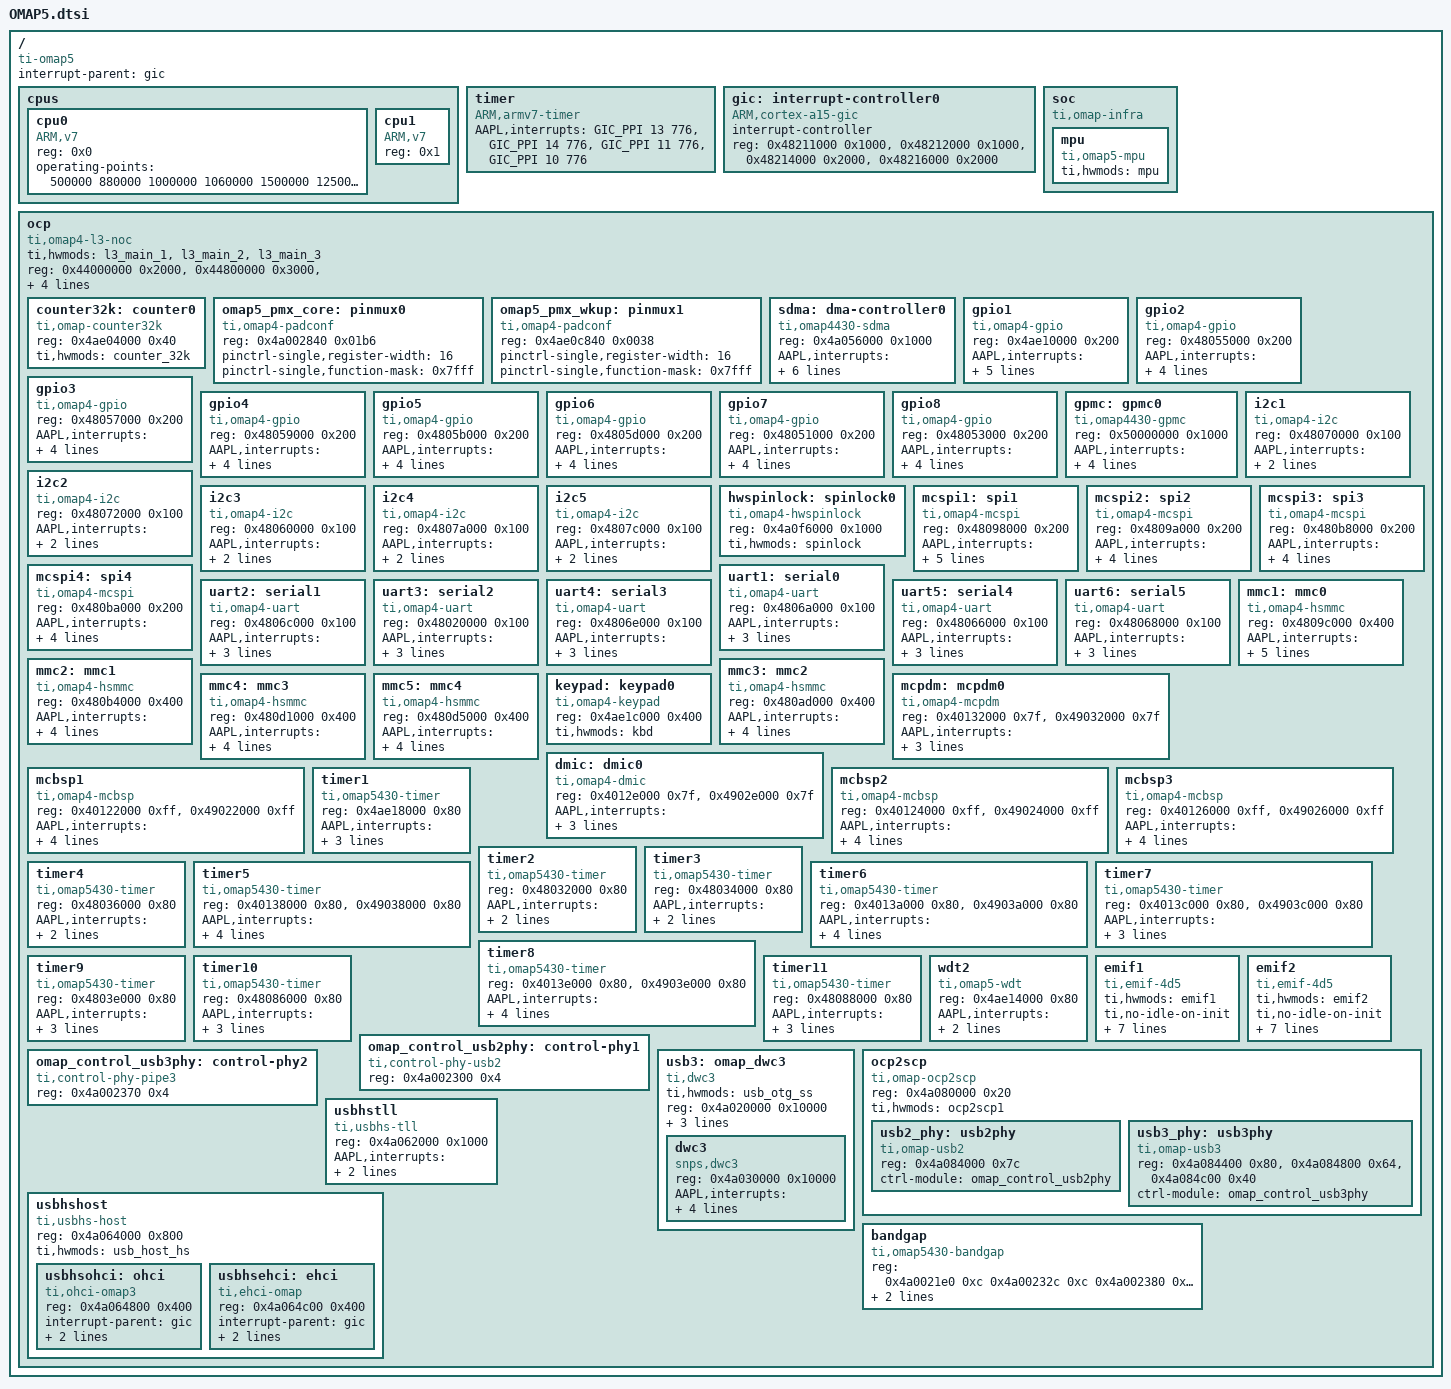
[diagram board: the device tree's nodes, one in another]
/*
 * Copyright (C) 2012 Texas Instruments Incorporated - http://www.ti.com/
 *
 * This program is free software; you can redistribute it and/or modify
 * it under the terms of the GNU General Public License version 2 as
 * published by the Free Software Foundation.
 * Based on "omap4.dtsi"
 */

#include <dt-bindings/interrupt-controller/arm-gic.h>

/ {
	compatible = "ti-omap5", "AppleARM";
	#address-cells = <1>;
	#size-cells = <1>;
	interrupt-parent = <&gic>;
	
	cpus {
		#address-cells = <1>;
		#size-cells = <0>;

		cpu0 {
			device_type = "cpu";
			compatible = "ARM,v7", "ARM,cortex-a15";
			reg = <0x0>;

			operating-points = <
				/* kHz    uV */
				500000  880000
				1000000 1060000
				1500000 1250000
			>;
		};
		cpu1 {
			device_type = "cpu";
			compatible = "ARM,v7", "ARM,cortex-a15";
			reg = <0x1>;
		};
	};

	timer {
		compatible = "ARM,armv7-timer";
		/* PPI secure/nonsecure IRQ */
		AAPL,interrupts = <GIC_PPI 13 776>,
			     <GIC_PPI 14 776>,
			     <GIC_PPI 11 776>,
			     <GIC_PPI 10 776>;
	};

	gic: interrupt-controller0 {
		compatible = "ARM,cortex-a15-gic";
		interrupt-controller;
		#interrupt-cells = <3>;
		reg = <0x48211000 0x1000>,
		      <0x48212000 0x1000>,
		      <0x48214000 0x2000>,
		      <0x48216000 0x2000>;
	};

	/*
	 * The soc node represents the soc top level view. It is uses for IPs
	 * that are not memory mapped in the MPU view or for the MPU itself.
	 */
	soc {
		compatible = "ti,omap-infra";
		mpu {
			compatible = "ti,omap5-mpu";
			ti,hwmods = "mpu";
		};
	};

	/*
	 * XXX: Use a flat representation of the OMAP3 interconnect.
	 * The real OMAP interconnect network is quite complex.
	 * Since that will not bring real advantage to represent that in DT for
	 * the moment, just use a fake OCP bus entry to represent the whole bus
	 * hierarchy.
	 */
	ocp {
		compatible = "ti,omap4-l3-noc", "simple-bus";
		#address-cells = <1>;
		#size-cells = <1>;
		ranges;
		ti,hwmods = "l3_main_1", "l3_main_2", "l3_main_3";
		reg = <0x44000000 0x2000>,
		      <0x44800000 0x3000>,
		      <0x45000000 0x4000>;
		AAPL,interrupts = <GIC_SPI 9 IRQ_TYPE_LEVEL_HIGH>,
			     <GIC_SPI 10 IRQ_TYPE_LEVEL_HIGH>;

		counter32k: counter0 {
			compatible = "ti,omap-counter32k";
			reg = <0x4ae04000 0x40>;
			ti,hwmods = "counter_32k";
		};

		omap5_pmx_core: pinmux0 {
			compatible = "ti,omap4-padconf", "pinctrl-single";
			reg = <0x4a002840 0x01b6>;
			#address-cells = <1>;
			#size-cells = <0>;
			pinctrl-single,register-width = <16>;
			pinctrl-single,function-mask = <0x7fff>;
		};
		omap5_pmx_wkup: pinmux1 {
			compatible = "ti,omap4-padconf", "pinctrl-single";
			reg = <0x4ae0c840 0x0038>;
			#address-cells = <1>;
			#size-cells = <0>;
			pinctrl-single,register-width = <16>;
			pinctrl-single,function-mask = <0x7fff>;
		};

		sdma: dma-controller0 {
			compatible = "ti,omap4430-sdma";
			reg = <0x4a056000 0x1000>;
			AAPL,interrupts = <GIC_SPI 12 IRQ_TYPE_LEVEL_HIGH>,
				     <GIC_SPI 13 IRQ_TYPE_LEVEL_HIGH>,
				     <GIC_SPI 14 IRQ_TYPE_LEVEL_HIGH>,
				     <GIC_SPI 15 IRQ_TYPE_LEVEL_HIGH>;
			#dma-cells = <1>;
			#dma-channels = <32>;
			#dma-requests = <127>;
		};
		
		gpio1: gpio1 {
			compatible = "ti,omap4-gpio";
			reg = <0x4ae10000 0x200>;
			AAPL,interrupts = <GIC_SPI 29 IRQ_TYPE_LEVEL_HIGH>;
			ti,hwmods = "gpio1";
			ti,gpio-always-on;
			gpio-controller;
			#gpio-cells = <2>;
			interrupt-controller;
			#interrupt-cells = <2>;
		};

		gpio2: gpio2 {
			compatible = "ti,omap4-gpio";
			reg = <0x48055000 0x200>;
			AAPL,interrupts = <GIC_SPI 30 IRQ_TYPE_LEVEL_HIGH>;
			ti,hwmods = "gpio2";
			gpio-controller;
			#gpio-cells = <2>;
			interrupt-controller;
			#interrupt-cells = <2>;
		};

		gpio3: gpio3 {
			compatible = "ti,omap4-gpio";
			reg = <0x48057000 0x200>;
			AAPL,interrupts = <GIC_SPI 31 IRQ_TYPE_LEVEL_HIGH>;
			ti,hwmods = "gpio3";
			gpio-controller;
			#gpio-cells = <2>;
			interrupt-controller;
			#interrupt-cells = <2>;
		};

		gpio4: gpio4 {
			compatible = "ti,omap4-gpio";
			reg = <0x48059000 0x200>;
			AAPL,interrupts = <GIC_SPI 32 IRQ_TYPE_LEVEL_HIGH>;
			ti,hwmods = "gpio4";
			gpio-controller;
			#gpio-cells = <2>;
			interrupt-controller;
			#interrupt-cells = <2>;
		};

		gpio5: gpio5 {
			compatible = "ti,omap4-gpio";
			reg = <0x4805b000 0x200>;
			AAPL,interrupts = <GIC_SPI 33 IRQ_TYPE_LEVEL_HIGH>;
			ti,hwmods = "gpio5";
			gpio-controller;
			#gpio-cells = <2>;
			interrupt-controller;
			#interrupt-cells = <2>;
		};

		gpio6: gpio6 {
			compatible = "ti,omap4-gpio";
			reg = <0x4805d000 0x200>;
			AAPL,interrupts = <GIC_SPI 34 IRQ_TYPE_LEVEL_HIGH>;
			ti,hwmods = "gpio6";
			gpio-controller;
			#gpio-cells = <2>;
			interrupt-controller;
			#interrupt-cells = <2>;
		};

		gpio7: gpio7 {
			compatible = "ti,omap4-gpio";
			reg = <0x48051000 0x200>;
			AAPL,interrupts = <GIC_SPI 35 IRQ_TYPE_LEVEL_HIGH>;
			ti,hwmods = "gpio7";
			gpio-controller;
			#gpio-cells = <2>;
			interrupt-controller;
			#interrupt-cells = <2>;
		};

		gpio8: gpio8 {
			compatible = "ti,omap4-gpio";
			reg = <0x48053000 0x200>;
			AAPL,interrupts = <GIC_SPI 121 IRQ_TYPE_LEVEL_HIGH>;
			ti,hwmods = "gpio8";
			gpio-controller;
			#gpio-cells = <2>;
			interrupt-controller;
			#interrupt-cells = <2>;
		};

		gpmc: gpmc0 {
			compatible = "ti,omap4430-gpmc";
			reg = <0x50000000 0x1000>;
			#address-cells = <2>;
			#size-cells = <1>;
			AAPL,interrupts = <GIC_SPI 20 IRQ_TYPE_LEVEL_HIGH>;
			gpmc,num-cs = <8>;
			gpmc,num-waitpins = <4>;
			ti,hwmods = "gpmc";
		};

		i2c1: i2c1 {
			compatible = "ti,omap4-i2c";
			reg = <0x48070000 0x100>;
			AAPL,interrupts = <GIC_SPI 56 IRQ_TYPE_LEVEL_HIGH>;
			#address-cells = <1>;
			#size-cells = <0>;
			ti,hwmods = "i2c1";
		};

		i2c2: i2c2 {
			compatible = "ti,omap4-i2c";
			reg = <0x48072000 0x100>;
			AAPL,interrupts = <GIC_SPI 57 IRQ_TYPE_LEVEL_HIGH>;
			#address-cells = <1>;
			#size-cells = <0>;
			ti,hwmods = "i2c2";
		};

		i2c3: i2c3 {
			compatible = "ti,omap4-i2c";
			reg = <0x48060000 0x100>;
			AAPL,interrupts = <GIC_SPI 61 IRQ_TYPE_LEVEL_HIGH>;
			#address-cells = <1>;
			#size-cells = <0>;
			ti,hwmods = "i2c3";
		};

		i2c4: i2c4 {
			compatible = "ti,omap4-i2c";
			reg = <0x4807a000 0x100>;
			AAPL,interrupts = <GIC_SPI 62 IRQ_TYPE_LEVEL_HIGH>;
			#address-cells = <1>;
			#size-cells = <0>;
			ti,hwmods = "i2c4";
		};

		i2c5: i2c5 {
			compatible = "ti,omap4-i2c";
			reg = <0x4807c000 0x100>;
			AAPL,interrupts = <GIC_SPI 60 IRQ_TYPE_LEVEL_HIGH>;
			#address-cells = <1>;
			#size-cells = <0>;
			ti,hwmods = "i2c5";
		};

		hwspinlock: spinlock0 {
			compatible = "ti,omap4-hwspinlock";
			reg = <0x4a0f6000 0x1000>;
			ti,hwmods = "spinlock";
		};

		mcspi1: spi1 {
			compatible = "ti,omap4-mcspi";
			reg = <0x48098000 0x200>;
			AAPL,interrupts = <GIC_SPI 65 IRQ_TYPE_LEVEL_HIGH>;
			#address-cells = <1>;
			#size-cells = <0>;
			ti,hwmods = "mcspi1";
			ti,spi-num-cs = <4>;
			dmas = <&sdma 35>,
			       <&sdma 36>,
			       <&sdma 37>,
			       <&sdma 38>,
			       <&sdma 39>,
			       <&sdma 40>,
			       <&sdma 41>,
			       <&sdma 42>;
			dma-names = "tx0", "rx0", "tx1", "rx1",
				    "tx2", "rx2", "tx3", "rx3";
		};

		mcspi2: spi2 {
			compatible = "ti,omap4-mcspi";
			reg = <0x4809a000 0x200>;
			AAPL,interrupts = <GIC_SPI 66 IRQ_TYPE_LEVEL_HIGH>;
			#address-cells = <1>;
			#size-cells = <0>;
			ti,hwmods = "mcspi2";
			ti,spi-num-cs = <2>;
			dmas = <&sdma 43>,
			       <&sdma 44>,
			       <&sdma 45>,
			       <&sdma 46>;
			dma-names = "tx0", "rx0", "tx1", "rx1";
		};

		mcspi3: spi3 {
			compatible = "ti,omap4-mcspi";
			reg = <0x480b8000 0x200>;
			AAPL,interrupts = <GIC_SPI 91 IRQ_TYPE_LEVEL_HIGH>;
			#address-cells = <1>;
			#size-cells = <0>;
			ti,hwmods = "mcspi3";
			ti,spi-num-cs = <2>;
			dmas = <&sdma 15>, <&sdma 16>;
			dma-names = "tx0", "rx0";
		};

		mcspi4: spi4 {
			compatible = "ti,omap4-mcspi";
			reg = <0x480ba000 0x200>;
			AAPL,interrupts = <GIC_SPI 48 IRQ_TYPE_LEVEL_HIGH>;
			#address-cells = <1>;
			#size-cells = <0>;
			ti,hwmods = "mcspi4";
			ti,spi-num-cs = <1>;
			dmas = <&sdma 70>, <&sdma 71>;
			dma-names = "tx0", "rx0";
		};

		uart1: serial0 {
			compatible = "ti,omap4-uart";
			reg = <0x4806a000 0x100>;
			AAPL,interrupts = <GIC_SPI 72 IRQ_TYPE_LEVEL_HIGH>;
			ti,hwmods = "uart1";
			clock-frequency = <48000000>;
		};

		uart2: serial1 {
			compatible = "ti,omap4-uart";
			reg = <0x4806c000 0x100>;
			AAPL,interrupts = <GIC_SPI 73 IRQ_TYPE_LEVEL_HIGH>;
			ti,hwmods = "uart2";
			clock-frequency = <48000000>;
		};

		uart3: serial2 {
			compatible = "ti,omap4-uart";
			reg = <0x48020000 0x100>;
			AAPL,interrupts = <GIC_SPI 74 IRQ_TYPE_LEVEL_HIGH>;
			ti,hwmods = "uart3";
			clock-frequency = <48000000>;
		};

		uart4: serial3 {
			compatible = "ti,omap4-uart";
			reg = <0x4806e000 0x100>;
			AAPL,interrupts = <GIC_SPI 70 IRQ_TYPE_LEVEL_HIGH>;
			ti,hwmods = "uart4";
			clock-frequency = <48000000>;
		};

		uart5: serial4 {
			compatible = "ti,omap4-uart";
			reg = <0x48066000 0x100>;
			AAPL,interrupts = <GIC_SPI 105 IRQ_TYPE_LEVEL_HIGH>;
			ti,hwmods = "uart5";
			clock-frequency = <48000000>;
		};

		uart6: serial5 {
			compatible = "ti,omap4-uart";
			reg = <0x48068000 0x100>;
			AAPL,interrupts = <GIC_SPI 106 IRQ_TYPE_LEVEL_HIGH>;
			ti,hwmods = "uart6";
			clock-frequency = <48000000>;
		};

		mmc1: mmc0 {
			compatible = "ti,omap4-hsmmc";
			reg = <0x4809c000 0x400>;
			AAPL,interrupts = <GIC_SPI 83 IRQ_TYPE_LEVEL_HIGH>;
			ti,hwmods = "mmc1";
			ti,dual-volt;
			ti,needs-special-reset;
			dmas = <&sdma 61>, <&sdma 62>;
			dma-names = "tx", "rx";
		};

		mmc2: mmc1 {
			compatible = "ti,omap4-hsmmc";
			reg = <0x480b4000 0x400>;
			AAPL,interrupts = <GIC_SPI 86 IRQ_TYPE_LEVEL_HIGH>;
			ti,hwmods = "mmc2";
			ti,needs-special-reset;
			dmas = <&sdma 47>, <&sdma 48>;
			dma-names = "tx", "rx";
		};

		mmc3: mmc2 {
			compatible = "ti,omap4-hsmmc";
			reg = <0x480ad000 0x400>;
			AAPL,interrupts = <GIC_SPI 94 IRQ_TYPE_LEVEL_HIGH>;
			ti,hwmods = "mmc3";
			ti,needs-special-reset;
			dmas = <&sdma 77>, <&sdma 78>;
			dma-names = "tx", "rx";
		};

		mmc4: mmc3 {
			compatible = "ti,omap4-hsmmc";
			reg = <0x480d1000 0x400>;
			AAPL,interrupts = <GIC_SPI 96 IRQ_TYPE_LEVEL_HIGH>;
			ti,hwmods = "mmc4";
			ti,needs-special-reset;
			dmas = <&sdma 57>, <&sdma 58>;
			dma-names = "tx", "rx";
		};

		mmc5: mmc4 {
			compatible = "ti,omap4-hsmmc";
			reg = <0x480d5000 0x400>;
			AAPL,interrupts = <GIC_SPI 59 IRQ_TYPE_LEVEL_HIGH>;
			ti,hwmods = "mmc5";
			ti,needs-special-reset;
			dmas = <&sdma 59>, <&sdma 60>;
			dma-names = "tx", "rx";
		};

		keypad: keypad0 {
			compatible = "ti,omap4-keypad";
			reg = <0x4ae1c000 0x400>;
			ti,hwmods = "kbd";
		};

		mcpdm: mcpdm0 {
			compatible = "ti,omap4-mcpdm";
			reg = <0x40132000 0x7f>, /* MPU private access */
			      <0x49032000 0x7f>; /* L3 Interconnect */
			reg-names = "mpu", "dma";
			AAPL,interrupts = <GIC_SPI 112 IRQ_TYPE_LEVEL_HIGH>;
			ti,hwmods = "mcpdm";
			dmas = <&sdma 65>,
			       <&sdma 66>;
			dma-names = "up_link", "dn_link";
		};

		dmic: dmic0 {
			compatible = "ti,omap4-dmic";
			reg = <0x4012e000 0x7f>, /* MPU private access */
			      <0x4902e000 0x7f>; /* L3 Interconnect */
			reg-names = "mpu", "dma";
			AAPL,interrupts = <GIC_SPI 114 IRQ_TYPE_LEVEL_HIGH>;
			ti,hwmods = "dmic";
			dmas = <&sdma 67>;
			dma-names = "up_link";
		};

		mcbsp1: mcbsp1 {
			compatible = "ti,omap4-mcbsp";
			reg = <0x40122000 0xff>, /* MPU private access */
			      <0x49022000 0xff>; /* L3 Interconnect */
			reg-names = "mpu", "dma";
			AAPL,interrupts = <GIC_SPI 17 IRQ_TYPE_LEVEL_HIGH>;
			interrupt-names = "common";
			ti,buffer-size = <128>;
			ti,hwmods = "mcbsp1";
			dmas = <&sdma 33>,
			       <&sdma 34>;
			dma-names = "tx", "rx";
		};

		mcbsp2: mcbsp2 {
			compatible = "ti,omap4-mcbsp";
			reg = <0x40124000 0xff>, /* MPU private access */
			      <0x49024000 0xff>; /* L3 Interconnect */
			reg-names = "mpu", "dma";
			AAPL,interrupts = <GIC_SPI 22 IRQ_TYPE_LEVEL_HIGH>;
			interrupt-names = "common";
			ti,buffer-size = <128>;
			ti,hwmods = "mcbsp2";
			dmas = <&sdma 17>,
			       <&sdma 18>;
			dma-names = "tx", "rx";
		};

		mcbsp3: mcbsp3 {
			compatible = "ti,omap4-mcbsp";
			reg = <0x40126000 0xff>, /* MPU private access */
			      <0x49026000 0xff>; /* L3 Interconnect */
			reg-names = "mpu", "dma";
			AAPL,interrupts = <GIC_SPI 23 IRQ_TYPE_LEVEL_HIGH>;
			interrupt-names = "common";
			ti,buffer-size = <128>;
			ti,hwmods = "mcbsp3";
			dmas = <&sdma 19>,
			       <&sdma 20>;
			dma-names = "tx", "rx";
		};

		timer1: timer1 {
			compatible = "ti,omap5430-timer";
			reg = <0x4ae18000 0x80>;
			AAPL,interrupts = <GIC_SPI 37 IRQ_TYPE_LEVEL_HIGH>;
			ti,hwmods = "timer1";
			ti,timer-alwon;
		};

		timer2: timer2 {
			compatible = "ti,omap5430-timer";
			reg = <0x48032000 0x80>;
			AAPL,interrupts = <GIC_SPI 38 IRQ_TYPE_LEVEL_HIGH>;
			ti,hwmods = "timer2";
		};

		timer3: timer3 {
			compatible = "ti,omap5430-timer";
			reg = <0x48034000 0x80>;
			AAPL,interrupts = <GIC_SPI 39 IRQ_TYPE_LEVEL_HIGH>;
			ti,hwmods = "timer3";
		};

		timer4: timer4 {
			compatible = "ti,omap5430-timer";
			reg = <0x48036000 0x80>;
			AAPL,interrupts = <GIC_SPI 40 IRQ_TYPE_LEVEL_HIGH>;
			ti,hwmods = "timer4";
		};

		timer5: timer5 {
			compatible = "ti,omap5430-timer";
			reg = <0x40138000 0x80>,
			      <0x49038000 0x80>;
			AAPL,interrupts = <GIC_SPI 41 IRQ_TYPE_LEVEL_HIGH>;
			ti,hwmods = "timer5";
			ti,timer-dsp;
			ti,timer-pwm;
		};

		timer6: timer6 {
			compatible = "ti,omap5430-timer";
			reg = <0x4013a000 0x80>,
			      <0x4903a000 0x80>;
			AAPL,interrupts = <GIC_SPI 42 IRQ_TYPE_LEVEL_HIGH>;
			ti,hwmods = "timer6";
			ti,timer-dsp;
			ti,timer-pwm;
		};

		timer7: timer7 {
			compatible = "ti,omap5430-timer";
			reg = <0x4013c000 0x80>,
			      <0x4903c000 0x80>;
			AAPL,interrupts = <GIC_SPI 43 IRQ_TYPE_LEVEL_HIGH>;
			ti,hwmods = "timer7";
			ti,timer-dsp;
		};

		timer8: timer8 {
			compatible = "ti,omap5430-timer";
			reg = <0x4013e000 0x80>,
			      <0x4903e000 0x80>;
			AAPL,interrupts = <GIC_SPI 44 IRQ_TYPE_LEVEL_HIGH>;
			ti,hwmods = "timer8";
			ti,timer-dsp;
			ti,timer-pwm;
		};

		timer9: timer9 {
			compatible = "ti,omap5430-timer";
			reg = <0x4803e000 0x80>;
			AAPL,interrupts = <GIC_SPI 45 IRQ_TYPE_LEVEL_HIGH>;
			ti,hwmods = "timer9";
			ti,timer-pwm;
		};

		timer10: timer10 {
			compatible = "ti,omap5430-timer";
			reg = <0x48086000 0x80>;
			AAPL,interrupts = <GIC_SPI 46 IRQ_TYPE_LEVEL_HIGH>;
			ti,hwmods = "timer10";
			ti,timer-pwm;
		};

		timer11: timer11 {
			compatible = "ti,omap5430-timer";
			reg = <0x48088000 0x80>;
			AAPL,interrupts = <GIC_SPI 47 IRQ_TYPE_LEVEL_HIGH>;
			ti,hwmods = "timer11";
			ti,timer-pwm;
		};

		wdt2: wdt2 {
			compatible = "ti,omap5-wdt", "ti,omap3-wdt";
			reg = <0x4ae14000 0x80>;
			AAPL,interrupts = <GIC_SPI 80 IRQ_TYPE_LEVEL_HIGH>;
			ti,hwmods = "wd_timer2";
		};

		emif1: emif1 {
			compatible	= "ti,emif-4d5";
			ti,hwmods	= "emif1";
			ti,no-idle-on-init;
			phy-type	= <2>; /* DDR PHY type: Intelli PHY */
			reg = <0x4c000000 0x400>;
			AAPL,interrupts = <GIC_SPI 110 IRQ_TYPE_LEVEL_HIGH>;
			hw-caps-read-idle-ctrl;
			hw-caps-ll-interface;
			hw-caps-temp-alert;
		};

		emif2: emif2 {
			compatible	= "ti,emif-4d5";
			ti,hwmods	= "emif2";
			ti,no-idle-on-init;
			phy-type	= <2>; /* DDR PHY type: Intelli PHY */
			reg = <0x4d000000 0x400>;
			AAPL,interrupts = <GIC_SPI 111 IRQ_TYPE_LEVEL_HIGH>;
			hw-caps-read-idle-ctrl;
			hw-caps-ll-interface;
			hw-caps-temp-alert;
		};

		omap_control_usb2phy: control-phy1 {
			compatible = "ti,control-phy-usb2";
			reg = <0x4a002300 0x4>;
			reg-names = "power";
		};

		omap_control_usb3phy: control-phy2 {
			compatible = "ti,control-phy-pipe3";
			reg = <0x4a002370 0x4>;
			reg-names = "power";
		};

		usb3: omap_dwc3 {
			compatible = "ti,dwc3";
			ti,hwmods = "usb_otg_ss";
			reg = <0x4a020000 0x10000>;
			AAPL,interrupts = <GIC_SPI 93 IRQ_TYPE_LEVEL_HIGH>;
			#address-cells = <1>;
			#size-cells = <1>;
			utmi-mode = <2>;
			ranges;
			dwc3 {
				compatible = "snps,dwc3";
				reg = <0x4a030000 0x10000>;
				AAPL,interrupts = <GIC_SPI 92 IRQ_TYPE_LEVEL_HIGH>;
				usb-phy = <&usb2_phy>, <&usb3_phy>;
				dr_mode = "peripheral";
				tx-fifo-resize;
			};
		};

		ocp2scp {
			compatible = "ti,omap-ocp2scp";
			#address-cells = <1>;
			#size-cells = <1>;
			reg = <0x4a080000 0x20>;
			ranges;
			ti,hwmods = "ocp2scp1";
			usb2_phy: usb2phy {
				compatible = "ti,omap-usb2";
				reg = <0x4a084000 0x7c>;
				ctrl-module = <&omap_control_usb2phy>;
			};

			usb3_phy: usb3phy {
				compatible = "ti,omap-usb3";
				reg = <0x4a084400 0x80>,
				      <0x4a084800 0x64>,
				      <0x4a084c00 0x40>;
				reg-names = "phy_rx", "phy_tx", "pll_ctrl";
				ctrl-module = <&omap_control_usb3phy>;
			};
		};

		usbhstll: usbhstll {
			compatible = "ti,usbhs-tll";
			reg = <0x4a062000 0x1000>;
			AAPL,interrupts = <GIC_SPI 78 IRQ_TYPE_LEVEL_HIGH>;
			ti,hwmods = "usb_tll_hs";
		};

		usbhshost: usbhshost {
			compatible = "ti,usbhs-host";
			reg = <0x4a064000 0x800>;
			ti,hwmods = "usb_host_hs";
			#address-cells = <1>;
			#size-cells = <1>;
			ranges;

			usbhsohci: ohci {
				compatible = "ti,ohci-omap3", "usb-ohci";
				reg = <0x4a064800 0x400>;
				interrupt-parent = <&gic>;
				AAPL,interrupts = <GIC_SPI 76 IRQ_TYPE_LEVEL_HIGH>;
			};

			usbhsehci: ehci {
				compatible = "ti,ehci-omap", "usb-ehci";
				reg = <0x4a064c00 0x400>;
				interrupt-parent = <&gic>;
				AAPL,interrupts = <GIC_SPI 77 IRQ_TYPE_LEVEL_HIGH>;
			};
		};

		bandgap {
			reg = <0x4a0021e0 0xc
			       0x4a00232c 0xc
			       0x4a002380 0x2c
			       0x4a0023C0 0x3c>;
			AAPL,interrupts = <GIC_SPI 126 IRQ_TYPE_LEVEL_HIGH>;
			compatible = "ti,omap5430-bandgap";
		};
	};
};
